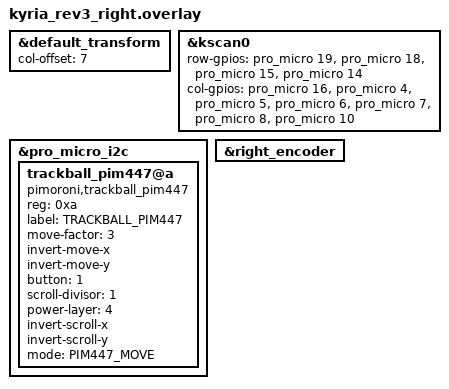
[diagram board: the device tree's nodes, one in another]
/*
 * Copyright (c) 2023 The ZMK Contributors
 *
 * SPDX-License-Identifier: MIT
 */

#include "kyria_rev3.dtsi"
#include <dt-bindings/zmk/trackball_pim447.h>

&default_transform {
    col-offset = <7>;
};

&kscan0 {
    row-gpios
    = <&pro_micro 19 (GPIO_ACTIVE_HIGH | GPIO_PULL_DOWN)>
    , <&pro_micro 18 (GPIO_ACTIVE_HIGH | GPIO_PULL_DOWN)>
    , <&pro_micro 15 (GPIO_ACTIVE_HIGH | GPIO_PULL_DOWN)>
    , <&pro_micro 14 (GPIO_ACTIVE_HIGH | GPIO_PULL_DOWN)>
    ;
    col-gpios
    = <&pro_micro 16 GPIO_ACTIVE_HIGH>
    , <&pro_micro 4  GPIO_ACTIVE_HIGH>
    , <&pro_micro 5  GPIO_ACTIVE_HIGH>
    , <&pro_micro 6  GPIO_ACTIVE_HIGH>
    , <&pro_micro 7  GPIO_ACTIVE_HIGH>
    , <&pro_micro 8  GPIO_ACTIVE_HIGH>
    , <&pro_micro 10 GPIO_ACTIVE_HIGH>
    ;
};
&pro_micro_i2c {
	status = "okay";
	trackball_pim447@a {
		compatible = "pimoroni,trackball_pim447";
		reg = <0xa>;
		label = "TRACKBALL_PIM447";
		move-factor = <3>;      // Increase pointer velocity (default: 1)
		invert-move-x;          // Invert pointer X axis (left is right, and vice versa)
		invert-move-y;          // Invert pointer Y axis (up is down, and vice versa)
		button = <1>;           // Send right-click when pressing the ball (default: 0, ie. left-click)
		//swap-axes;              // Swap X and Y axes (horizontal is vertical, and vice versa)
		scroll-divisor = <1>;   // Increase wheel velocity (default: 2)
    power-layer = <4>;       // layer whose activity switches on 3V3 output of the N!N or 0 for always on; default: 0
		invert-scroll-x;        // Invert wheel X axis (left is right, and vice versa)
		invert-scroll-y;        // Invert wheel Y axis (up is down, and vice versa)
		mode = <PIM447_MOVE>;   // Act as mouse pointer at startup (PIM447_Scroll for a pointer)
		//mode = <PIM447_SCROLL>;   // Act as mouse pointer at startup (PIM447_Scroll for a pointer)
	};
};

&right_encoder {
    status = "okay";
};
